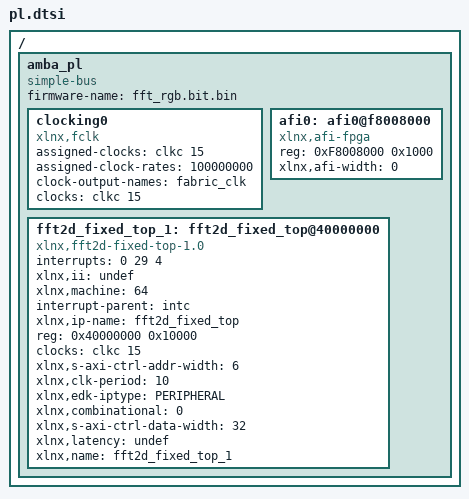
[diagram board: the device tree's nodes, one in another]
/ {
	amba_pl: amba_pl {
		ranges;
		compatible = "simple-bus";
		#address-cells = <1>;
		#size-cells = <1>;
		firmware-name = "fft_rgb.bit.bin";
		clocking0: clocking0 {
			compatible = "xlnx,fclk";
			assigned-clocks = <&clkc 15>;
			assigned-clock-rates = <100000000>;
			#clock-cells = <0>;
			clock-output-names = "fabric_clk";
			clocks = <&clkc 15>;
		};
		afi0: afi0@f8008000 {
			status = "okay";
			compatible = "xlnx,afi-fpga";
			#address-cells = <1>;
			reg = <0xF8008000 0x1000>;
			#size-cells = <0>;
			xlnx,afi-width = <0>;
		};
		fft2d_fixed_top_1: fft2d_fixed_top@40000000 {
			interrupts = < 0 29 4 >;
			compatible = "xlnx,fft2d-fixed-top-1.0";
			xlnx,ii = "undef";
			xlnx,machine = <64>;
			interrupt-parent = <&intc>;
			xlnx,ip-name = "fft2d_fixed_top";
			reg = <0x40000000 0x10000>;
			clocks = <&clkc 15>;
			xlnx,s-axi-ctrl-addr-width = <6>;
			xlnx,clk-period = <10>;
			xlnx,edk-iptype = "PERIPHERAL";
			status = "okay";
			clock-names = "ap_clk";
			interrupt-names = "interrupt";
			xlnx,combinational = <0>;
			xlnx,s-axi-ctrl-data-width = <32>;
			xlnx,latency = "undef";
			xlnx,name = "fft2d_fixed_top_1";
		};
	};
};
